AUTOSAR XML (schema 4-0-3)
standard types defined: uint8, Boolean, UInt16, UInt32, UInt8
package /AUTOSAR_Platform/DataConstrs
  range DC_Boolean: raw 0..1
  range DC_UInt16: raw 0..65535
  range DC_UInt8: raw 0..255
package /PATAC/Facility/DataTypes/Implementation
  compu method COMPU_Boolean: 0=FALSE, 1=TRUE
  unit NoUnit: factor-si-to-unit=1, offset-si-to-unit=0
package /PATAC/MSM/ComponentTypes
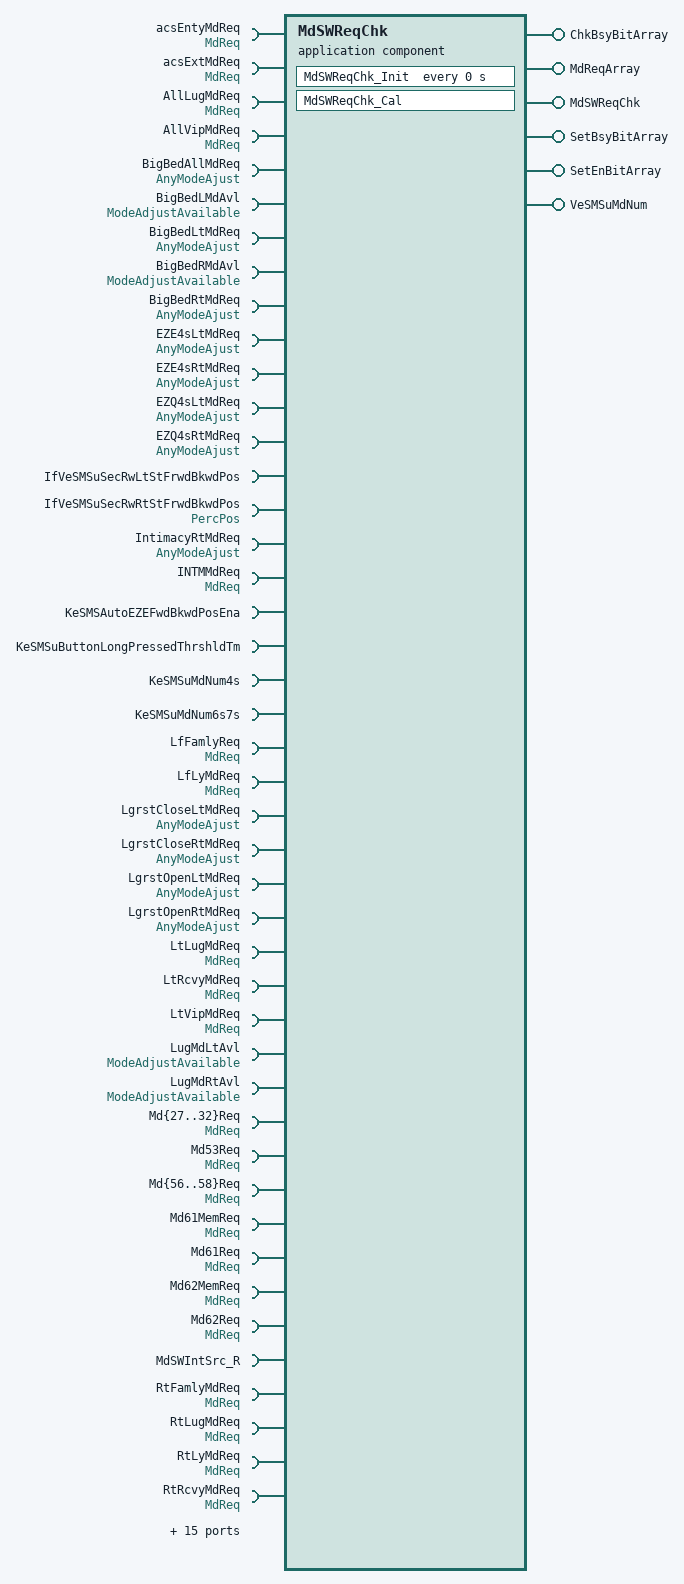
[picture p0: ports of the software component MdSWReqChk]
  application sw component type MdSWReqChk
    6 x provide port:
      ChkBsyBitArray: nonqueued-sender-com-spec=data-element=ChkBsyBitArray/Val, provided-interface=ChkBsyBitArray
      MdReqArray: nonqueued-sender-com-spec=data-element=MdReqArray/Val, provided-interface=MdReqArray
      MdSWReqChk: server-com-spec{operation=Cal, queue-length=1}, provided-interface=MdSWReqChk
      SetBsyBitArray: nonqueued-sender-com-spec=data-element=SetBsyBitArray/Val, provided-interface=SetBsyBitArray
      SetEnBitArray: nonqueued-sender-com-spec=data-element=SetEnBitArray/Val, provided-interface=SetEnBitArray
      VeSMSuMdNum: nonqueued-sender-com-spec=data-element=VeSMSuMdNum/Val, provided-interface=VeSMSuMdNum
    66 x require port:
      acsEntyMdReq: nonqueued-receiver-com-spec{data-element=MdReq/Val, filter=data-filter-type=ALWAYS, init-value=0}, required-interface=MdReq
      acsExtMdReq: nonqueued-receiver-com-spec{data-element=MdReq/Val, filter=data-filter-type=ALWAYS, init-value=0}, required-interface=MdReq
      AllLugMdReq: nonqueued-receiver-com-spec{data-element=MdReq/Val, filter=data-filter-type=ALWAYS, init-value=0}, required-interface=MdReq
      AllVipMdReq: nonqueued-receiver-com-spec{data-element=MdReq/Val, filter=data-filter-type=ALWAYS, init-value=0}, required-interface=MdReq
      BigBedAllMdReq: nonqueued-receiver-com-spec{data-element=AnyModeAjust/Val, filter=data-filter-type=ALWAYS, init-value=0}, required-interface=AnyModeAjust
      BigBedLMdAvl: nonqueued-receiver-com-spec{data-element=ModeAdjustAvailable/Val, filter=data-filter-type=ALWAYS, init-value=0}, required-interface=ModeAdjustAvailable
      BigBedLtMdReq: nonqueued-receiver-com-spec{data-element=AnyModeAjust/Val, filter=data-filter-type=ALWAYS, init-value=0}, required-interface=AnyModeAjust
      BigBedRMdAvl: nonqueued-receiver-com-spec{data-element=ModeAdjustAvailable/Val, filter=data-filter-type=ALWAYS, init-value=0}, required-interface=ModeAdjustAvailable
      BigBedRtMdReq: nonqueued-receiver-com-spec{data-element=AnyModeAjust/Val, filter=data-filter-type=ALWAYS, init-value=0}, required-interface=AnyModeAjust
      EZE4sLtMdReq: nonqueued-receiver-com-spec{data-element=AnyModeAjust/Val, filter=data-filter-type=ALWAYS, init-value=0}, required-interface=AnyModeAjust
      EZE4sRtMdReq: nonqueued-receiver-com-spec{data-element=AnyModeAjust/Val, filter=data-filter-type=ALWAYS, init-value=0}, required-interface=AnyModeAjust
      EZQ4sLtMdReq: nonqueued-receiver-com-spec{data-element=AnyModeAjust/Val, filter=data-filter-type=ALWAYS, init-value=0}, required-interface=AnyModeAjust
      EZQ4sRtMdReq: nonqueued-receiver-com-spec{data-element=AnyModeAjust/Val, filter=data-filter-type=ALWAYS, init-value=0}, required-interface=AnyModeAjust
      IfVeSMSuSecRwLtStFrwdBkwdPos: nonqueued-receiver-com-spec{data-element=IfVeSMSuSecRwLtStFrwdBkwdPos/Val, filter=data-filter-type=ALWAYS, init-value=0}, required-interface=IfVeSMSuSecRwLtStFrwdBkwdPos
      IfVeSMSuSecRwRtStFrwdBkwdPos: nonqueued-receiver-com-spec{data-element=PercPos/Val, filter=data-filter-type=ALWAYS, init-value=0}, required-interface=PercPos
      IntimacyRtMdReq: nonqueued-receiver-com-spec{data-element=AnyModeAjust/Val, filter=data-filter-type=ALWAYS, init-value=0}, required-interface=AnyModeAjust
      INTMMdReq: nonqueued-receiver-com-spec{data-element=MdReq/Val, filter=data-filter-type=ALWAYS, init-value=0}, required-interface=MdReq
      KeSMSAutoEZEFwdBkwdPosEna: parameter-require-com-spec{init-value=0, parameter=KeSMSAutoEZEFwdBkwdPosEna/Val}, required-interface=KeSMSAutoEZEFwdBkwdPosEna
      KeSMSuButtonLongPressedThrshldTm: parameter-require-com-spec{init-value=100, parameter=KeSMSuButtonLongPressedThrshldTm/Val}, required-interface=KeSMSuButtonLongPressedThrshldTm
      KeSMSuMdNum4s: parameter-require-com-spec{init-value=16, parameter=KeSMSuMdNum4s/Val}, required-interface=KeSMSuMdNum4s
      KeSMSuMdNum6s7s: parameter-require-com-spec{init-value=22, parameter=KeSMSuMdNum6s7s/Val}, required-interface=KeSMSuMdNum6s7s
      LfFamlyReq: nonqueued-receiver-com-spec{data-element=MdReq/Val, filter=data-filter-type=ALWAYS, init-value=0}, required-interface=MdReq
      LfLyMdReq: nonqueued-receiver-com-spec{data-element=MdReq/Val, filter=data-filter-type=ALWAYS, init-value=0}, required-interface=MdReq
      LgrstCloseLtMdReq: nonqueued-receiver-com-spec{data-element=AnyModeAjust/Val, filter=data-filter-type=ALWAYS, init-value=0}, required-interface=AnyModeAjust
      LgrstCloseRtMdReq: nonqueued-receiver-com-spec{data-element=AnyModeAjust/Val, filter=data-filter-type=ALWAYS, init-value=0}, required-interface=AnyModeAjust
      LgrstOpenLtMdReq: nonqueued-receiver-com-spec{data-element=AnyModeAjust/Val, filter=data-filter-type=ALWAYS, init-value=0}, required-interface=AnyModeAjust
      LgrstOpenRtMdReq: nonqueued-receiver-com-spec{data-element=AnyModeAjust/Val, filter=data-filter-type=ALWAYS, init-value=0}, required-interface=AnyModeAjust
      LtLugMdReq: nonqueued-receiver-com-spec{data-element=MdReq/Val, filter=data-filter-type=ALWAYS, init-value=0}, required-interface=MdReq
      LtRcvyMdReq: nonqueued-receiver-com-spec{data-element=MdReq/Val, filter=data-filter-type=ALWAYS, init-value=0}, required-interface=MdReq
      LtVipMdReq: nonqueued-receiver-com-spec{data-element=MdReq/Val, filter=data-filter-type=ALWAYS, init-value=0}, required-interface=MdReq
      LugMdLtAvl: nonqueued-receiver-com-spec{data-element=ModeAdjustAvailable/Val, filter=data-filter-type=ALWAYS, init-value=0}, required-interface=ModeAdjustAvailable
      LugMdRtAvl: nonqueued-receiver-com-spec{data-element=ModeAdjustAvailable/Val, filter=data-filter-type=ALWAYS, init-value=0}, required-interface=ModeAdjustAvailable
      Md{27..32}Req: nonqueued-receiver-com-spec{data-element=MdReq/Val, filter=data-filter-type=ALWAYS, init-value=0}, required-interface=MdReq
      Md53Req: nonqueued-receiver-com-spec{data-element=MdReq/Val, filter=data-filter-type=ALWAYS, init-value=0}, required-interface=MdReq
      Md{56..58}Req: nonqueued-receiver-com-spec{data-element=MdReq/Val, filter=data-filter-type=ALWAYS, init-value=0}, required-interface=MdReq
      Md61MemReq: nonqueued-receiver-com-spec{data-element=MdReq/Val, filter=data-filter-type=ALWAYS, init-value=0}, required-interface=MdReq
      Md61Req: nonqueued-receiver-com-spec{data-element=MdReq/Val, filter=data-filter-type=ALWAYS, init-value=0}, required-interface=MdReq
      Md62MemReq: nonqueued-receiver-com-spec{data-element=MdReq/Val, filter=data-filter-type=ALWAYS, init-value=0}, required-interface=MdReq
      Md62Req: nonqueued-receiver-com-spec{data-element=MdReq/Val, filter=data-filter-type=ALWAYS, init-value=0}, required-interface=MdReq
      MdSWIntSrc_R: nonqueued-receiver-com-spec{data-element=MdSWIntSrc_R/Val, filter=data-filter-type=ALWAYS, init-value=0}, required-interface=MdSWIntSrc_R
      RtFamlyMdReq: nonqueued-receiver-com-spec{data-element=MdReq/Val, filter=data-filter-type=ALWAYS, init-value=0}, required-interface=MdReq
      RtLugMdReq: nonqueued-receiver-com-spec{data-element=MdReq/Val, filter=data-filter-type=ALWAYS, init-value=0}, required-interface=MdReq
      RtLyMdReq: nonqueued-receiver-com-spec{data-element=MdReq/Val, filter=data-filter-type=ALWAYS, init-value=0}, required-interface=MdReq
      RtRcvyMdReq: nonqueued-receiver-com-spec{data-element=MdReq/Val, filter=data-filter-type=ALWAYS, init-value=0}, required-interface=MdReq
      RtVipMdReq: nonqueued-receiver-com-spec{data-element=MdReq/Val, filter=data-filter-type=ALWAYS, init-value=0}, required-interface=MdReq
      StNumFlg: required-interface=StNumFlg
        required-com-specs:
          data-element=Is4s, filter=data-filter-type=ALWAYS, init-value=0
          data-element=Is6s, filter=data-filter-type=ALWAYS, init-value=0
          data-element=Is6s7s, filter=data-filter-type=ALWAYS, init-value=0
          data-element=Is7s, filter=data-filter-type=ALWAYS, init-value=0
      SwIntAcsEnty: nonqueued-receiver-com-spec{data-element=IntEnable/Val, filter=data-filter-type=ALWAYS, init-value=0}, required-interface=IntEnable
      SwIntAcsExt: nonqueued-receiver-com-spec{data-element=IntEnable/Val, filter=data-filter-type=ALWAYS, init-value=0}, required-interface=IntEnable
      SwIntAllLug: nonqueued-receiver-com-spec{data-element=IntEnable/Val, filter=data-filter-type=ALWAYS, init-value=0}, required-interface=IntEnable
      SwIntLfRcvy: nonqueued-receiver-com-spec{data-element=IntEnable/Val, filter=data-filter-type=ALWAYS, init-value=0}, required-interface=IntEnable
      SwIntLfVip: nonqueued-receiver-com-spec{data-element=IntEnable/Val, filter=data-filter-type=ALWAYS, init-value=0}, required-interface=IntEnable
      SwIntRtRcvy: nonqueued-receiver-com-spec{data-element=IntEnable/Val, filter=data-filter-type=ALWAYS, init-value=0}, required-interface=IntEnable
      SwIntRtVip: nonqueued-receiver-com-spec{data-element=IntEnable/Val, filter=data-filter-type=ALWAYS, init-value=0}, required-interface=IntEnable
      VipExitMdLtAvl: nonqueued-receiver-com-spec{data-element=ModeAdjustAvailable/Val, filter=data-filter-type=ALWAYS, init-value=0}, required-interface=ModeAdjustAvailable
      VipExitMdRtAvl: nonqueued-receiver-com-spec{data-element=ModeAdjustAvailable/Val, filter=data-filter-type=ALWAYS, init-value=0}, required-interface=ModeAdjustAvailable
      VipMdLtAvl: nonqueued-receiver-com-spec{data-element=ModeAdjustAvailable/Val, filter=data-filter-type=ALWAYS, init-value=0}, required-interface=ModeAdjustAvailable
      VipMdRtAvl: nonqueued-receiver-com-spec{data-element=ModeAdjustAvailable/Val, filter=data-filter-type=ALWAYS, init-value=0}, required-interface=ModeAdjustAvailable
      WelcomeBkwdMdReq: nonqueued-receiver-com-spec{data-element=AnyModeAjust/Val, filter=data-filter-type=ALWAYS, init-value=0}, required-interface=AnyModeAjust
      WelcomeFwdMdReq: nonqueued-receiver-com-spec{data-element=AnyModeAjust/Val, filter=data-filter-type=ALWAYS, init-value=0}, required-interface=AnyModeAjust
    behavior MdSWReqChk_InternalBehavior
      operation invoked event OIT_MdSWReqChk_Cal_MdSWReqChk_Cal: start-on-event=MdSWReqChk_Cal, operation=MdSWReqChk.Cal
      timing event MdSWReqChk_InitEvent: start-on-event=MdSWReqChk_Init, period=0
      runnable MdSWReqChk_Cal
        data-receive-point-by-arguments:
          65 x access:
            REC_acsEntyMdReq_Val: accessed-variable=acsEntyMdReq.Val
            REC_acsExtMdReq_Val: accessed-variable=acsExtMdReq.Val
            REC_AllLugMdReq_Val: accessed-variable=AllLugMdReq.Val
            REC_AllVipMdReq_Val: accessed-variable=AllVipMdReq.Val
            REC_BigBedAllMdReq_Val: accessed-variable=BigBedAllMdReq.Val
            REC_BigBedLMdAvl_Val: accessed-variable=BigBedLMdAvl.Val
            REC_BigBedLtMdReq_Val: accessed-variable=BigBedLtMdReq.Val
            REC_BigBedRMdAvl_Val: accessed-variable=BigBedRMdAvl.Val
            REC_BigBedRtMdReq_Val: accessed-variable=BigBedRtMdReq.Val
            REC_EZE4sLtMdReq_Val: accessed-variable=EZE4sLtMdReq.Val
            REC_EZE4sRtMdReq_Val: accessed-variable=EZE4sRtMdReq.Val
            REC_EZQ4sLtMdReq_Val: accessed-variable=EZQ4sLtMdReq.Val
            REC_EZQ4sRtMdReq_Val: accessed-variable=EZQ4sRtMdReq.Val
            REC_IfVeSMSuSecRwLtStFrwdBkwdPos_Val: accessed-variable=IfVeSMSuSecRwLtStFrwdBkwdPos.Val
            REC_IfVeSMSuSecRwRtStFrwdBkwdPos_Val: accessed-variable=IfVeSMSuSecRwRtStFrwdBkwdPos.Val
            REC_IntimacyRtMdReq_Val: accessed-variable=IntimacyRtMdReq.Val
            REC_INTMMdReq_Val: accessed-variable=INTMMdReq.Val
            REC_LfFamlyReq_Val: accessed-variable=LfFamlyReq.Val
            REC_LfLyMdReq_Val: accessed-variable=LfLyMdReq.Val
            REC_LgrstCloseLtMdReq_Val: accessed-variable=LgrstCloseLtMdReq.Val
            REC_LgrstCloseRtMdReq_Val: accessed-variable=LgrstCloseRtMdReq.Val
            REC_LgrstOpenLtMdReq_Val: accessed-variable=LgrstOpenLtMdReq.Val
            REC_LgrstOpenRtMdReq_Val: accessed-variable=LgrstOpenRtMdReq.Val
            REC_LtLugMdReq_Val: accessed-variable=LtLugMdReq.Val
            REC_LtRcvyMdReq_Val: accessed-variable=LtRcvyMdReq.Val
            REC_LtVipMdReq_Val: accessed-variable=LtVipMdReq.Val
            REC_LugMdLtAvl_Val: accessed-variable=LugMdLtAvl.Val
            REC_LugMdRtAvl_Val: accessed-variable=LugMdRtAvl.Val
            REC_Md{27..32}Req_Val: accessed-variable=Md{27..32}Req.Val
            REC_Md53Req_Val: accessed-variable=Md53Req.Val
            REC_Md{56..58}Req_Val: accessed-variable=Md{56..58}Req.Val
            REC_Md61MemReq_Val: accessed-variable=Md61MemReq.Val
            REC_Md61Req_Val: accessed-variable=Md61Req.Val
            REC_Md62MemReq_Val: accessed-variable=Md62MemReq.Val
            REC_Md62Req_Val: accessed-variable=Md62Req.Val
            REC_MdSWIntSrc_R_Val: accessed-variable=MdSWIntSrc_R.Val
            REC_RtFamlyMdReq_Val: accessed-variable=RtFamlyMdReq.Val
            REC_RtLugMdReq_Val: accessed-variable=RtLugMdReq.Val
            REC_RtLyMdReq_Val: accessed-variable=RtLyMdReq.Val
            REC_RtRcvyMdReq_Val: accessed-variable=RtRcvyMdReq.Val
            REC_RtVipMdReq_Val: accessed-variable=RtVipMdReq.Val
            REC_StNumFlg_Is4s: accessed-variable=StNumFlg.Is4s
            REC_StNumFlg_Is6s: accessed-variable=StNumFlg.Is6s
            REC_StNumFlg_Is6s7s: accessed-variable=StNumFlg.Is6s7s
            REC_StNumFlg_Is7s: accessed-variable=StNumFlg.Is7s
            REC_SwIntAcsEnty_Val: accessed-variable=SwIntAcsEnty.Val
            REC_SwIntAcsExt_Val: accessed-variable=SwIntAcsExt.Val
            REC_SwIntAllLug_Val: accessed-variable=SwIntAllLug.Val
            REC_SwIntLfRcvy_Val: accessed-variable=SwIntLfRcvy.Val
            REC_SwIntLfVip_Val: accessed-variable=SwIntLfVip.Val
            REC_SwIntRtRcvy_Val: accessed-variable=SwIntRtRcvy.Val
            REC_SwIntRtVip_Val: accessed-variable=SwIntRtVip.Val
            REC_VipExitMdLtAvl_Val: accessed-variable=VipExitMdLtAvl.Val
            REC_VipExitMdRtAvl_Val: accessed-variable=VipExitMdRtAvl.Val
            REC_VipMdLtAvl_Val: accessed-variable=VipMdLtAvl.Val
            REC_VipMdRtAvl_Val: accessed-variable=VipMdRtAvl.Val
            REC_WelcomeBkwdMdReq_Val: accessed-variable=WelcomeBkwdMdReq.Val
            REC_WelcomeFwdMdReq_Val: accessed-variable=WelcomeFwdMdReq.Val
        data-send-points:
          5 x access:
            SEND_ChkBsyBitArray_Val: accessed-variable=ChkBsyBitArray.Val
            SEND_MdReqArray_Val: accessed-variable=MdReqArray.Val
            SEND_SetBsyBitArray_Val: accessed-variable=SetBsyBitArray.Val
            SEND_SetEnBitArray_Val: accessed-variable=SetEnBitArray.Val
            SEND_VeSMSuMdNum_Val: accessed-variable=VeSMSuMdNum.Val
        4 x parameter access:
          PA_KeSMSAutoEZEFwdBkwdPosEna_Val: accessed-parameter=KeSMSAutoEZEFwdBkwdPosEna.Val
          PA_KeSMSuButtonLongPressedThrshldTm_Val: accessed-parameter=KeSMSuButtonLongPressedThrshldTm.Val
          PA_KeSMSuMdNum4s_Val: accessed-parameter=KeSMSuMdNum4s.Val
          PA_KeSMSuMdNum6s7s_Val: accessed-parameter=KeSMSuMdNum6s7s.Val
      runnable MdSWReqChk_Init
        4 x parameter access:
          PA_KeSMSAutoEZEFwdBkwdPosEna_Val: accessed-parameter=KeSMSAutoEZEFwdBkwdPosEna.Val
          PA_KeSMSuButtonLongPressedThrshldTm_Val: accessed-parameter=KeSMSuButtonLongPressedThrshldTm.Val
          PA_KeSMSuMdNum4s_Val: accessed-parameter=KeSMSuMdNum4s.Val
          PA_KeSMSuMdNum6s7s_Val: accessed-parameter=KeSMSuMdNum6s7s.Val
  swc implementation MdSWReqChk_Implementation: behavior=MdSWReqChk_InternalBehavior
    code-descriptors:
      code Default: artifact-descriptors=autosar-engineering-object={short-label=Default, category=SWSRC}
package /PATAC/MSM/DataTypes/ImplementationDataTypes
  impl type IntEnable: category=VALUE, base-type=Boolean, sw-calibration-access=READ-ONLY, type-emitter=RTE
package /PATAC/MSM/ModeAdjust/CalPortInterface
  4 x parameter interface:
    KeSMSAutoEZEFwdBkwdPosEna
      parameter data prototype Val: sw-calibration-access=READ-WRITE, type=UInt16
    KeSMSuButtonLongPressedThrshldTm
      parameter data prototype Val: sw-calibration-access=READ-WRITE, type=UInt8
    KeSMSuMdNum4s
      parameter data prototype Val: sw-calibration-access=READ-WRITE, type=UInt8
    KeSMSuMdNum6s7s
      parameter data prototype Val: sw-calibration-access=READ-WRITE, type=UInt8
package /PATAC/MSM/ModeAdjust/DataType
  impl type array1x32_Boolean: category=ARRAY, sw-calibration-access=READ-ONLY, type-emitter=RTE
    element Element: array-size=32, array-size-semantics=FIXED-SIZE, implementation-data-type=Boolean
  impl type array1x32_Uint32: category=ARRAY, sw-calibration-access=READ-ONLY, type-emitter=RTE
    element Element: array-size=32, array-size-semantics=FIXED-SIZE, implementation-data-type=UInt32
package /PATAC/MSM/ModeAdjust/PortInterface
  client server interface MdSWReqChk
    operation Cal
      arg modestate32: type=UInt32, direction=IN, server-argument-impl-policy=USE-ARGUMENT-TYPE
  12 x sender receiver interface:
    AnyModeAjust: invalidation-policy{data-element=AnyModeAjust/Val, handle-invalid=DONT-INVALIDATE}
      data Val: type=Boolean
    ChkBsyBitArray: invalidation-policy{data-element=ChkBsyBitArray/Val, handle-invalid=DONT-INVALIDATE}
      data Val: type=array1x32_Uint32
    IntEnable: invalidation-policy{data-element=IntEnable/Val, handle-invalid=DONT-INVALIDATE}
      data Val: type=IntEnable
    MdReq: invalidation-policy{data-element=MdReq/Val, handle-invalid=DONT-INVALIDATE}
      data Val: type=Boolean
    MdReqArray: invalidation-policy{data-element=MdReqArray/Val, handle-invalid=DONT-INVALIDATE}
      data Val: type=array1x32_Boolean
    MdSWIntSrc_R: invalidation-policy{data-element=MdSWIntSrc_R/Val, handle-invalid=DONT-INVALIDATE}  # bit0-acsext bit1-acsentry bit2-ltvip bit3-Rtvip bit4-lug bit5-ltrcvy bit6-rtrcvy
      data Val: type=UInt16
    ModeAdjustAvailable: invalidation-policy{data-element=ModeAdjustAvailable/Val, handle-invalid=DONT-INVALIDATE}
      data Val: type=Boolean
    PercPos: invalidation-policy{data-element=PercPos/Val, handle-invalid=DONT-INVALIDATE}
      data Val: type=UInt16
    SetBsyBitArray: invalidation-policy{data-element=SetBsyBitArray/Val, handle-invalid=DONT-INVALIDATE}
      data Val: type=array1x32_Uint32
    SetEnBitArray: invalidation-policy{data-element=SetEnBitArray/Val, handle-invalid=DONT-INVALIDATE}
      data Val: type=array1x32_Uint32
    StNumFlg
      4 x data, all with type=Boolean:
        Is4s
        Is6s
        Is6s7s
        Is7s
      invalidation-policys:
        data-element=Is4s, handle-invalid=DONT-INVALIDATE
        data-element=Is6s, handle-invalid=DONT-INVALIDATE
        data-element=Is6s7s, handle-invalid=DONT-INVALIDATE
        data-element=Is7s, handle-invalid=DONT-INVALIDATE
    VeSMSuMdNum: invalidation-policy{data-element=VeSMSuMdNum/Val, handle-invalid=DONT-INVALIDATE}
      data Val: type=UInt8
package /PATAC/MSM/PortInterfaces
  sender receiver interface IfVeSMSuSecRwLtStFrwdBkwdPos: invalidation-policy{data-element=IfVeSMSuSecRwLtStFrwdBkwdPos/Val, handle-invalid=DONT-INVALIDATE}
    data Val: type=UInt16
